# RFCORE_SFR_CM register map
Vendor: Texas Instruments
Peripheral module from a debugger description file (folder cc2538).
Registers are 32-bit, access per field, no defined reset value unless marked. A register's access mark holds for its fields unless they carry their own. Offsets are as the file gives them; lines under a group give offsets from that group; [hi:lo] are bit positions; {n}, {i} and the like mark numbered series; 'fields as' and 'values as' point back to an identical list; <NAME> marks a mode.

## RFCORE_SFR — Register fields should be considered static unless otherwise noted as dynamic.
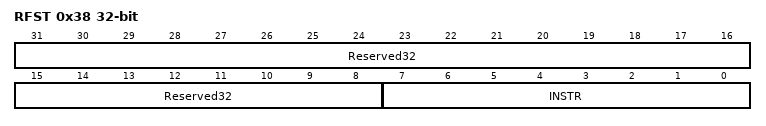
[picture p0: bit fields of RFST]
0x38 RFST — RF CSMA-CA/strobe processor
  [31:8] Reserved32 ro — This register is 8 bits in a 32-bit address space.
  [7:0] INSTR rw — Data written to this register is written to the CSP instruction memory. Reading this register returns the CSP instruction currently being executed.
